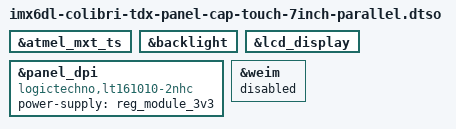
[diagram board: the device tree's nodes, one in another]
// SPDX-License-Identifier: GPL-2.0-only OR MIT
/*
 * Copyright (c) Toradex
 *
 * Toradex Capacitive Touch Display 7" Parallel connected through the 40-way
 * Unified Interface Display and 10-way Capacitive Touch Interface connectors
 * (as featured on Iris v2 and Aster v1.1 carrier boards).
 *
 * https://developer.toradex.com/hardware/accessories/displays/capacitive-touch-display-7inch-parallel/
 * https://docs.toradex.com/104497-7-inch-parallel-capacitive-touch-display-800x480-datasheet.pdf
 * https://www.toradex.com/accessories/capacitive-touch-display-7-inch-parallel
 */

/dts-v1/;
/plugin/;

&atmel_mxt_ts {
	status = "okay";
};

&backlight {
	status = "okay";
};

&lcd_display {
	status = "okay";
};

&panel_dpi {
	compatible = "logictechno,lt161010-2nhc";
	power-supply = <&reg_module_3v3>;

	status = "okay";
};

&weim {
	status = "disabled";
};
